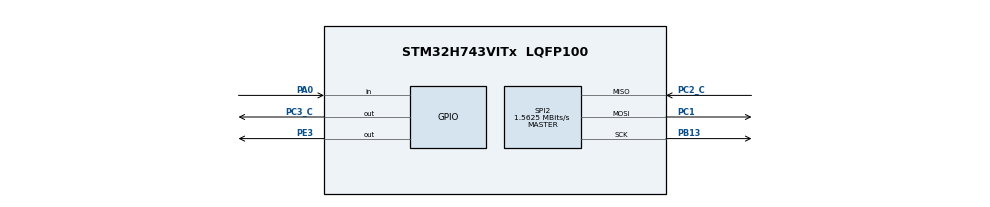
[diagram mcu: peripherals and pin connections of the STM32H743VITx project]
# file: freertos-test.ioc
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CORTEX_M7.default_mode_Activation=1
Dma.Request0=SPI2_RX
Dma.Request1=SPI2_TX
Dma.SPI2_RX.0.Direction=DMA_PERIPH_TO_MEMORY
Dma.SPI2_RX.0.EventEnable=DISABLE
Dma.SPI2_RX.0.FIFOMode=DMA_FIFOMODE_DISABLE
Dma.SPI2_RX.0.Instance=DMA1_Stream0
Dma.SPI2_RX.0.MemDataAlignment=DMA_MDATAALIGN_BYTE
Dma.SPI2_RX.0.MemInc=DMA_MINC_ENABLE
Dma.SPI2_RX.0.Mode=DMA_NORMAL
Dma.SPI2_RX.0.PeriphDataAlignment=DMA_PDATAALIGN_BYTE
Dma.SPI2_RX.0.PeriphInc=DMA_PINC_DISABLE
Dma.SPI2_RX.0.Polarity=HAL_DMAMUX_REQ_GEN_RISING
Dma.SPI2_RX.0.Priority=DMA_PRIORITY_LOW
Dma.SPI2_RX.0.RequestNumber=1
Dma.SPI2_RX.0.SignalID=NONE
Dma.SPI2_RX.0.SyncEnable=DISABLE
Dma.SPI2_RX.0.SyncPolarity=HAL_DMAMUX_SYNC_NO_EVENT
Dma.SPI2_RX.0.SyncRequestNumber=1
Dma.SPI2_RX.0.SyncSignalID=NONE
Dma.SPI2_TX.1.Direction=DMA_MEMORY_TO_PERIPH
Dma.SPI2_TX.1.EventEnable=DISABLE
Dma.SPI2_TX.1.FIFOMode=DMA_FIFOMODE_DISABLE
Dma.SPI2_TX.1.Instance=DMA1_Stream1
Dma.SPI2_TX.1.MemDataAlignment=DMA_MDATAALIGN_BYTE
Dma.SPI2_TX.1.MemInc=DMA_MINC_ENABLE
Dma.SPI2_TX.1.Mode=DMA_NORMAL
Dma.SPI2_TX.1.PeriphDataAlignment=DMA_PDATAALIGN_BYTE
Dma.SPI2_TX.1.PeriphInc=DMA_PINC_DISABLE
Dma.SPI2_TX.1.Polarity=HAL_DMAMUX_REQ_GEN_RISING
Dma.SPI2_TX.1.Priority=DMA_PRIORITY_LOW
Dma.SPI2_TX.1.RequestNumber=1
Dma.SPI2_TX.1.SignalID=NONE
Dma.SPI2_TX.1.SyncEnable=DISABLE
Dma.SPI2_TX.1.SyncPolarity=HAL_DMAMUX_SYNC_NO_EVENT
Dma.SPI2_TX.1.SyncRequestNumber=1
Dma.SPI2_TX.1.SyncSignalID=NONE
FREERTOS.Tasks01=defaultTask,24,128,StartDefaultTask,Default,NULL,Dynamic,NULL,NULL
Mcu.Family=STM32H7
Mcu.Name=STM32H743VITx
Mcu.Package=LQFP100
NVIC.DMA1_Stream0_IRQn=true\:5\:0\:false\:false\:true\:true\:false\:true\:true
NVIC.DMA1_Stream1_IRQn=true\:5\:0\:false\:false\:true\:true\:false\:true\:true
NVIC.PriorityGroup=NVIC_PRIORITYGROUP_4
NVIC.SPI2_IRQn=true\:5\:0\:false\:false\:true\:true\:false\:true\:true
NVIC.TIM1_UP_IRQn=true\:15\:0\:false\:false\:true\:false\:false\:true\:true
NVIC.TimeBase=TIM1_UP_IRQn
NVIC.TimeBaseIP=TIM1
PA0.Signal=GPIO_Input
PA13\ (JTMS/SWDIO).Mode=Serial_Wire
PA13\ (JTMS/SWDIO).Signal=DEBUG_JTMS-SWDIO
PA14\ (JTCK/SWCLK).Mode=Serial_Wire
PA14\ (JTCK/SWCLK).Signal=DEBUG_JTCK-SWCLK
PB13.Mode=Full_Duplex_Master
PB13.Signal=SPI2_SCK
PC1.Mode=Full_Duplex_Master
PC1.Signal=SPI2_MOSI
PC2_C.Mode=Full_Duplex_Master
PC2_C.Signal=SPI2_MISO
PC3_C.Signal=GPIO_Output
PE3.Signal=GPIO_Output
PH0-OSC_IN\ (PH0).Mode=HSE-External-Oscillator
PH0-OSC_IN\ (PH0).Signal=RCC_OSC_IN
PH1-OSC_OUT\ (PH1).Mode=HSE-External-Oscillator
PH1-OSC_OUT\ (PH1).Signal=RCC_OSC_OUT
ProjectManager.HeapSize=0x200
ProjectManager.StackSize=0x400
ProjectManager.TargetToolchain=CMake
RCC.ADCFreq_Value=200000000
RCC.APB1Freq_Value=100000000
RCC.APB2Freq_Value=100000000
RCC.APB3Freq_Value=100000000
RCC.APB4Freq_Value=100000000
RCC.CortexFreq_Value=400000000
RCC.D1PPRE=RCC_APB3_DIV2
RCC.D2PPRE1=RCC_APB1_DIV2
RCC.D2PPRE2=RCC_APB2_DIV2
RCC.D3PPRE=RCC_APB4_DIV2
RCC.DIVM1=3
RCC.DIVM2=3
RCC.DIVN1=100
RCC.DIVN2=100
RCC.DIVP2=4
RCC.HCLKFreq_Value=200000000
RCC.HPRE=RCC_HCLK_DIV2
RCC.HSE_VALUE=24000000
RCC.PLLSourceVirtual=RCC_PLLSOURCE_HSE
RCC.SPI123CLockSelection=RCC_SPI123CLKSOURCE_PLL2
RCC.SYSCLKFreq_VALUE=400000000
RCC.SYSCLKSource=RCC_SYSCLKSOURCE_PLLCLK
RCC.USBFreq_Value=400000000
SPI2.BaudRatePrescaler=SPI_BAUDRATEPRESCALER_128
SPI2.CalculateBaudRate=1.5625 MBits/s
SPI2.DataSize=SPI_DATASIZE_8BIT
SPI2.Direction=SPI_DIRECTION_2LINES
SPI2.Mode=SPI_MODE_MASTER
SPI2.VirtualType=VM_MASTER
VP_FREERTOS_VS_CMSIS_V2.Mode=CMSIS_V2
VP_MEMORYMAP_VS_MEMORYMAP.Mode=CurAppReg
VP_SYS_VS_tim1.Mode=TIM1
board=custom

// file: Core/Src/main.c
/* USER CODE BEGIN Header */
/**
  ******************************************************************************
  * @file           : main.c
  * @brief          : Main program body
  ******************************************************************************
  * @attention
  *
  * Copyright (c) 2026 STMicroelectronics.
  * All rights reserved.
  *
  * This software is licensed under terms that can be found in the LICENSE file
  * in the root directory of this software component.
  * If no LICENSE file comes with this software, it is provided AS-IS.
  *
  ******************************************************************************
  */
/* USER CODE END Header */
#include "main.h"
#include "FreeRTOS.h"
#include "cmsis_os2.h"
#include "dma.h"
#include "spi.h"
#include "gpio.h"

void SystemClock_Config(void);
static void MPU_Config(void);
void MX_FREERTOS_Init(void);

int main(void)
{

  /* MPU Configuration--------------------------------------------------------*/
      MPU_Config();

  /* MCU Configuration--------------------------------------------------------*/

  /* Reset of all peripherals, Initializes the Flash interface and the Systick. */
  HAL_Init();

  /* Configure the system clock */
  SystemClock_Config();

  /* Initialize all configured peripherals */
  MX_GPIO_Init();
  MX_DMA_Init();
  MX_SPI2_Init();

  /* Init scheduler */
  osKernelInitialize();  /* Call init function for freertos objects (in cmsis_os2.c) */
  MX_FREERTOS_Init();

  /* Start scheduler */
  osKernelStart();

  /* We should never get here as control is now taken by the scheduler */

  /* Infinite loop */
  while (1)
  {

  }
}

void SystemClock_Config(void)
{
  RCC_OscInitTypeDef RCC_OscInitStruct = {0};
  RCC_ClkInitTypeDef RCC_ClkInitStruct = {0};

  /** Supply configuration update enable
  */
  HAL_PWREx_ConfigSupply(PWR_LDO_SUPPLY);

  /** Configure the main internal regulator output voltage
  */
  __HAL_PWR_VOLTAGESCALING_CONFIG(PWR_REGULATOR_VOLTAGE_SCALE1);

  while(!__HAL_PWR_GET_FLAG(PWR_FLAG_VOSRDY)) {}

  /** Initializes the RCC Oscillators according to the specified parameters
  * in the RCC_OscInitTypeDef structure.
  */
  RCC_OscInitStruct.OscillatorType = RCC_OSCILLATORTYPE_HSE;
  RCC_OscInitStruct.HSEState = RCC_HSE_ON;
  RCC_OscInitStruct.PLL.PLLState = RCC_PLL_ON;
  RCC_OscInitStruct.PLL.PLLSource = RCC_PLLSOURCE_HSE;
  RCC_OscInitStruct.PLL.PLLM = 3;
  RCC_OscInitStruct.PLL.PLLN = 100;
  RCC_OscInitStruct.PLL.PLLP = 2;
  RCC_OscInitStruct.PLL.PLLQ = 2;
  RCC_OscInitStruct.PLL.PLLR = 2;
  RCC_OscInitStruct.PLL.PLLRGE = RCC_PLL1VCIRANGE_3;
  RCC_OscInitStruct.PLL.PLLVCOSEL = RCC_PLL1VCOWIDE;
  RCC_OscInitStruct.PLL.PLLFRACN = 0;
  if (HAL_RCC_OscConfig(&RCC_OscInitStruct) != HAL_OK)
  {
    Error_Handler();
  }

  /** Initializes the CPU, AHB and APB buses clocks
  */
  RCC_ClkInitStruct.ClockType = RCC_CLOCKTYPE_HCLK|RCC_CLOCKTYPE_SYSCLK
                              |RCC_CLOCKTYPE_PCLK1|RCC_CLOCKTYPE_PCLK2
                              |RCC_CLOCKTYPE_D3PCLK1|RCC_CLOCKTYPE_D1PCLK1;
  RCC_ClkInitStruct.SYSCLKSource = RCC_SYSCLKSOURCE_PLLCLK;
  RCC_ClkInitStruct.SYSCLKDivider = RCC_SYSCLK_DIV1;
  RCC_ClkInitStruct.AHBCLKDivider = RCC_HCLK_DIV2;
  RCC_ClkInitStruct.APB3CLKDivider = RCC_APB3_DIV2;
  RCC_ClkInitStruct.APB1CLKDivider = RCC_APB1_DIV2;
  RCC_ClkInitStruct.APB2CLKDivider = RCC_APB2_DIV2;
  RCC_ClkInitStruct.APB4CLKDivider = RCC_APB4_DIV2;

  if (HAL_RCC_ClockConfig(&RCC_ClkInitStruct, FLASH_LATENCY_2) != HAL_OK)
  {
    Error_Handler();
  }
}

 /* MPU Configuration */

void MPU_Config(void)
{
  MPU_Region_InitTypeDef MPU_InitStruct = {0};

  /* Disables the MPU */
  HAL_MPU_Disable();

  /** Initializes and configures the Region and the memory to be protected
  */
  MPU_InitStruct.Enable = MPU_REGION_ENABLE;
  MPU_InitStruct.Number = MPU_REGION_NUMBER0;
  MPU_InitStruct.BaseAddress = 0x0;
  MPU_InitStruct.Size = MPU_REGION_SIZE_4GB;
  MPU_InitStruct.SubRegionDisable = 0x87;
  MPU_InitStruct.TypeExtField = MPU_TEX_LEVEL0;
  MPU_InitStruct.AccessPermission = MPU_REGION_NO_ACCESS;
  MPU_InitStruct.DisableExec = MPU_INSTRUCTION_ACCESS_DISABLE;
  MPU_InitStruct.IsShareable = MPU_ACCESS_SHAREABLE;
  MPU_InitStruct.IsCacheable = MPU_ACCESS_NOT_CACHEABLE;
  MPU_InitStruct.IsBufferable = MPU_ACCESS_NOT_BUFFERABLE;

  HAL_MPU_ConfigRegion(&MPU_InitStruct);
  /* Enables the MPU */
  HAL_MPU_Enable(MPU_PRIVILEGED_DEFAULT);

}

void HAL_TIM_PeriodElapsedCallback(TIM_HandleTypeDef *htim)
{
  if (htim->Instance == TIM1)
  {
    HAL_IncTick();
  }
}

void Error_Handler(void)
{
  __disable_irq();
  while (1)
  {
  }
}

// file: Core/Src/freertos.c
/* USER CODE BEGIN Header */
/**
  ******************************************************************************
  * File Name          : freertos.c
  * Description        : Code for freertos applications
  ******************************************************************************
  * @attention
  *
  * Copyright (c) 2026 STMicroelectronics.
  * All rights reserved.
  *
  * This software is licensed under terms that can be found in the LICENSE file
  * in the root directory of this software component.
  * If no LICENSE file comes with this software, it is provided AS-IS.
  *
  ******************************************************************************
  */
/* USER CODE END Header */

#include "FreeRTOS.h"
#include "task.h"
#include "main.h"
#include "FreeRTOS.h"
#include "cmsis_os2.h"

/* USER CODE BEGIN Includes */
#include "os_tasks_create.h"
/* USER CODE END Includes */

/* Definitions for defaultTask */
osThreadId_t defaultTaskHandle;
const osThreadAttr_t defaultTask_attributes = {
  .name = "defaultTask",
  .stack_size = 128 * 4,
  .priority = (osPriority_t) osPriorityNormal,
};

void StartDefaultTask(void *argument);

void MX_FREERTOS_Init(void); /* (MISRA C 2004 rule 8.1) */

void MX_FREERTOS_Init(void) {

  /* Create the thread(s) */
  /* creation of defaultTask */
  defaultTaskHandle = osThreadNew(StartDefaultTask, NULL, &defaultTask_attributes);

  /* USER CODE BEGIN RTOS_THREADS */
  /* SPI 框架 + 传感器模块任务统一创建 */
  OsTasks_Create();
  /* USER CODE END RTOS_THREADS */

}

void StartDefaultTask(void *argument)
{
  for(;;)
  {
    osDelay(1);
  }
}
